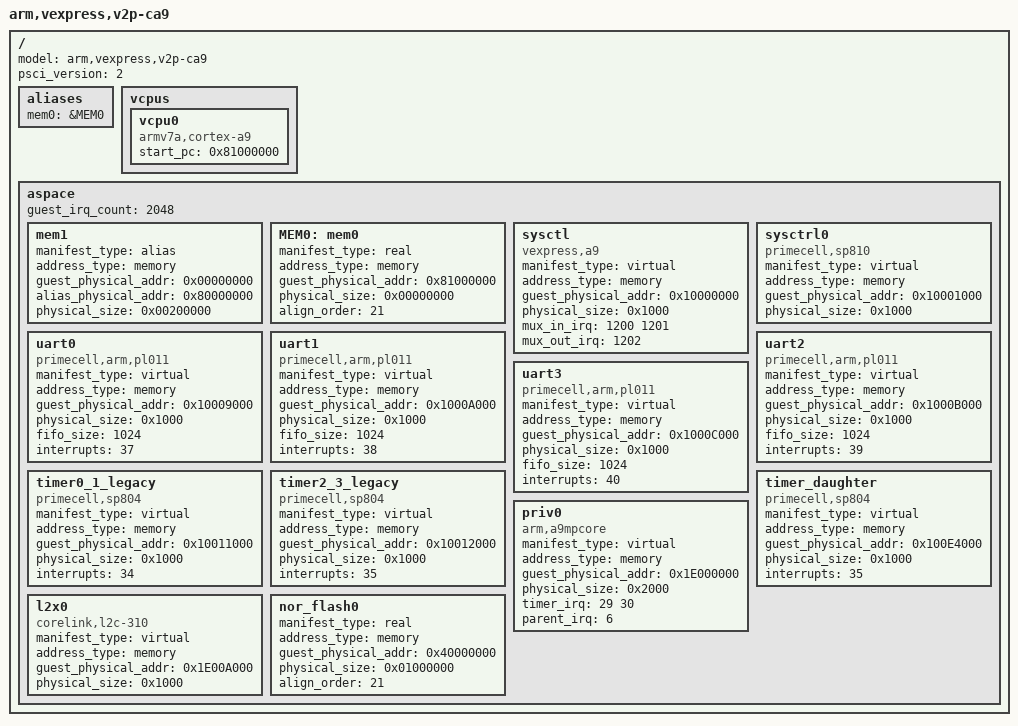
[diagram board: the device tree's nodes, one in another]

/dts-v1/;

/ {
	model = "arm,vexpress,v2p-ca9";
	device_type = "guest";
	psci_version = <2>;

	aliases {
		mem0 = &MEM0;
	};

	vcpus {
		vcpu0 {
			device_type = "vcpu";
			compatible = "armv7a,cortex-a9";
			start_pc = <0x81000000>;
		};
	};

	aspace {
		guest_irq_count = <2048>;

		/* Assume the REMAP region is mapped to DDR */
		mem1 {
			manifest_type = "alias";
			address_type = "memory";
			guest_physical_addr = <0x00000000>;
			alias_physical_addr = <0x80000000>;
			physical_size = <0x00200000>;
			device_type = "ram";
		};

		MEM0: mem0 {
			manifest_type = "real";
			address_type = "memory";
			guest_physical_addr = <0x81000000>;
			physical_size = <0x00000000>; /* Override this before guest creation */
			align_order = <21>; /* Align alloced memory to 2MB */
			device_type = "alloced_ram";
		};

		sysctl {
			manifest_type = "virtual";
			address_type = "memory";
			guest_physical_addr = <0x10000000>;
			physical_size = <0x1000>;
			device_type = "sys";
			compatible = "vexpress,a9";
			mux_in_irq = <1200 1201>;
			mux_out_irq = <1202>;
		};

		sysctrl0 {
			manifest_type = "virtual";
			address_type = "memory";
			guest_physical_addr = <0x10001000>;
			physical_size = <0x1000>;
			device_type = "sys";
			compatible = "primecell,sp810";
		};

		uart0 {
			manifest_type = "virtual";
			address_type = "memory";
			guest_physical_addr = <0x10009000>;
			physical_size = <0x1000>;
			device_type = "serial";
			compatible = "primecell,arm,pl011";
			fifo_size = <1024>;
			interrupts = <37>;
		};

		uart1 {
			manifest_type = "virtual";
			address_type = "memory";
			guest_physical_addr = <0x1000A000>;
			physical_size = <0x1000>;
			device_type = "serial";
			compatible = "primecell,arm,pl011";
			fifo_size = <1024>;
			interrupts = <38>;
		};

		uart2 {
			manifest_type = "virtual";
			address_type = "memory";
			guest_physical_addr = <0x1000B000>;
			physical_size = <0x1000>;
			device_type = "serial";
			compatible = "primecell,arm,pl011";
			fifo_size = <1024>;
			interrupts = <39>;
		};

		uart3 {
			manifest_type = "virtual";
			address_type = "memory";
			guest_physical_addr = <0x1000C000>;
			physical_size = <0x1000>;
			device_type = "serial";
			compatible = "primecell,arm,pl011";
			fifo_size = <1024>;
			interrupts = <40>;
		};

		timer0_1_legacy {
			manifest_type = "virtual";
			address_type = "memory";
			guest_physical_addr = <0x10011000>;
			physical_size = <0x1000>;
			device_type = "timer";
			compatible = "primecell,sp804";
			interrupts = <34>;
		};

		timer2_3_legacy {
			manifest_type = "virtual";
			address_type = "memory";
			guest_physical_addr = <0x10012000>;
			physical_size = <0x1000>;
			device_type = "timer";
			compatible = "primecell,sp804";
			interrupts = <35>;
		};

		timer_daughter {
			manifest_type = "virtual";
			address_type = "memory";
			guest_physical_addr = <0x100E4000>;
			physical_size = <0x1000>;
			device_type = "timer";
			compatible = "primecell,sp804";
			interrupts = <35>;
		};

		priv0 {
			manifest_type = "virtual";
			address_type = "memory";
			guest_physical_addr = <0x1E000000>;
			physical_size = <0x2000>;
			device_type = "misc";
			compatible = "arm,a9mpcore";
			timer_irq = <29 30>;
			parent_irq = <6>;
		};

		l2x0 {
			manifest_type = "virtual";
			address_type = "memory";
			guest_physical_addr = <0x1E00A000>;
			physical_size = <0x1000>;
			device_type = "cache";
			compatible = "corelink,l2c-310";
		};

		nor_flash0 {
			manifest_type = "real";
			address_type = "memory";
			guest_physical_addr = <0x40000000>;
			physical_size = <0x01000000>;
			device_type = "alloced_rom";
			align_order = <21>; /* Align alloced memory to 2MB */
		};
	};
};
